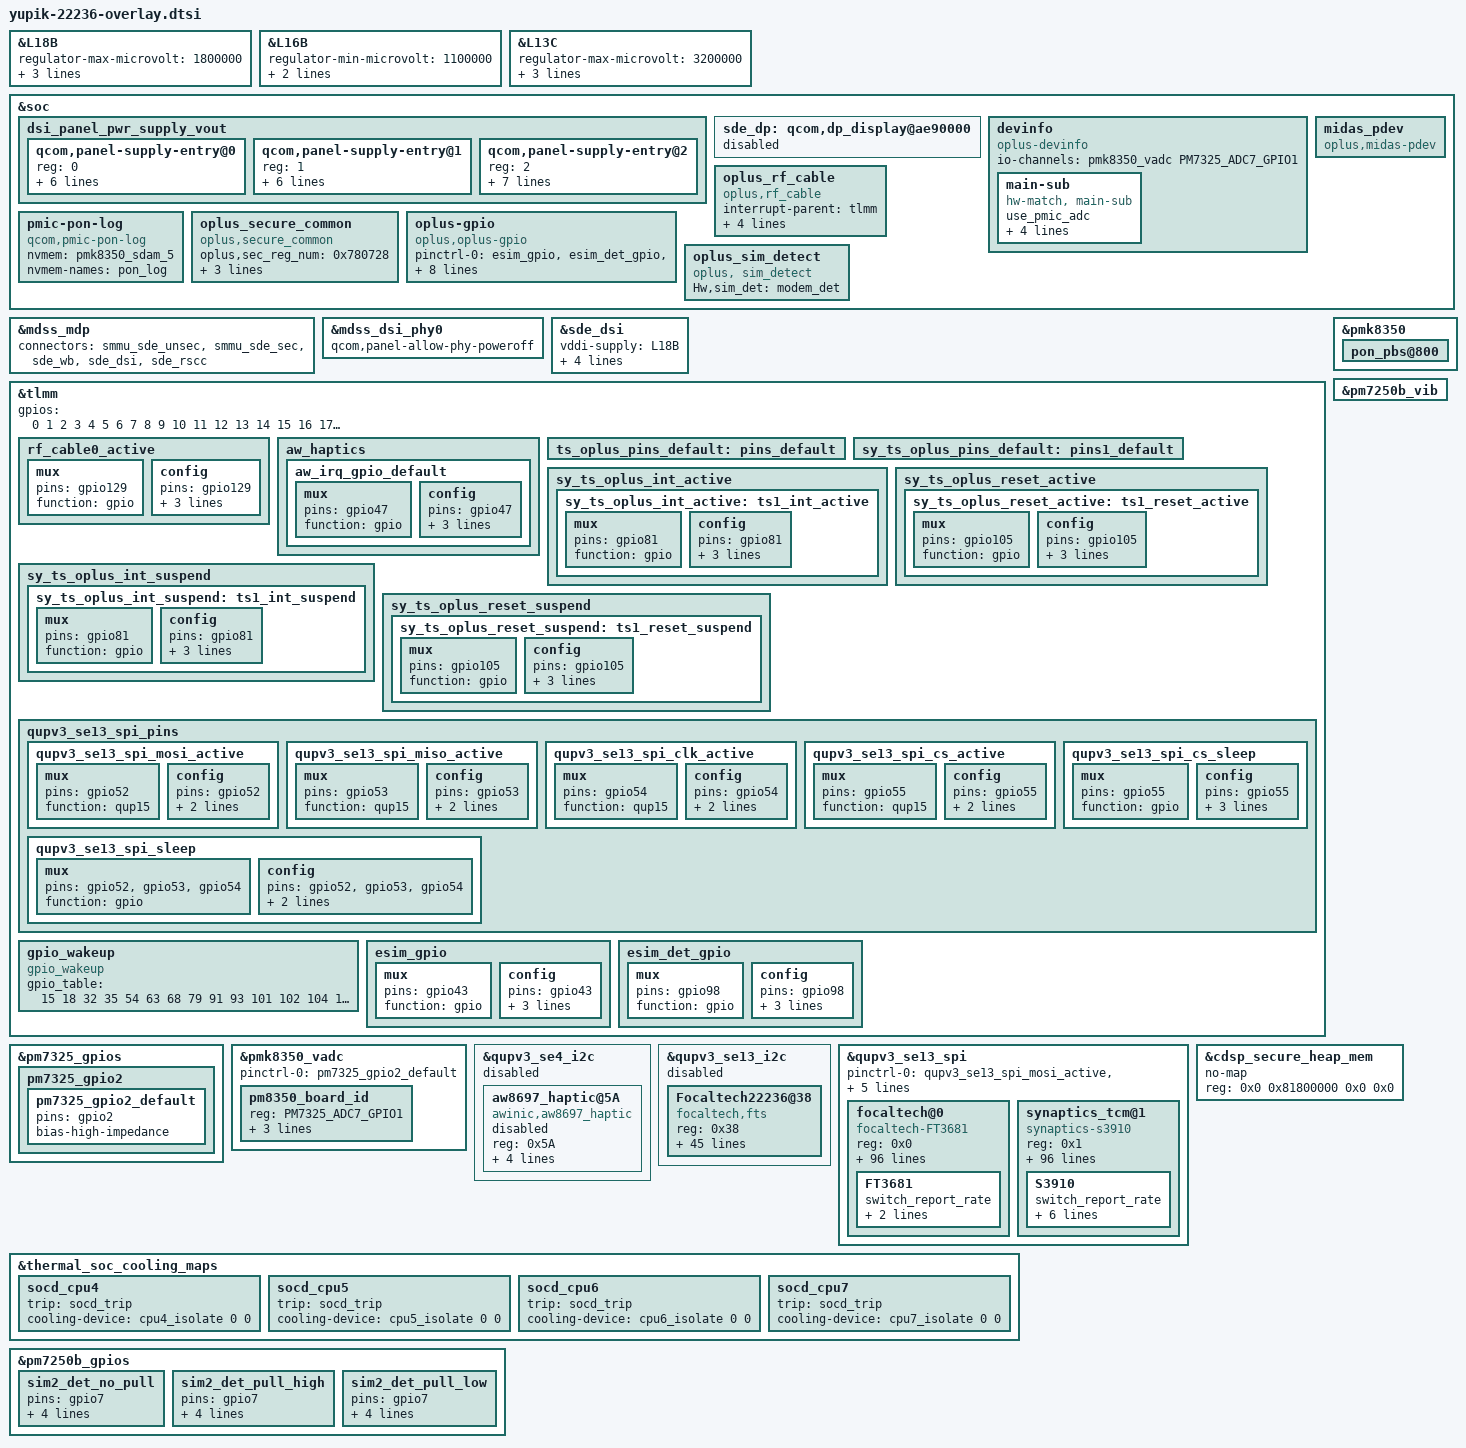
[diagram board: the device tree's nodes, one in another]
/*#ifdef OPLUS_FEATURE_SENSOR_DRIVER*/
#include "sensor/garbo-sensor-22236.dtsi"
/*#endif*/

//#ifdef OPLUS_FEATURE_UFF_FINGERPRINT
#include "oplus_uff_fingerprint_garbo.dtsi"
//#endif

//#ifdef OPLUS_FEATURE_CHG_BASIC
#include "charge/garbo_charge.dtsi"
//#endif

//#ifdef OPLUS_BUG_STABILITY
#include "dsi_panel-oplus22236-tm-ili7838a-1080-2412-dsc-cmd.dtsi"
#include "dsi_panel-oplus22236-boe-nt37705-1080-2412-dsc-cmd.dtsi"
//VDDI
&L18B {
	regulator-max-microvolt = <1800000>;
	qcom,init-voltage = <1800000>;
	qcom,proxy-consumer-enable;
	qcom,proxy-consumer-current = <243000>;
};
//VDDR(VOUT)
&L16B {
	regulator-min-microvolt = <1100000>;
	regulator-man-microvolt = <1300000>;
	qcom,min-dropout-voltage = <70000>;
};
//VCI
&L13C {
	regulator-max-microvolt = <3200000>;
	qcom,init-voltage = <3000000>;
	qcom,proxy-consumer-enable;
	qcom,proxy-consumer-current = <10000>;
};
&soc {
	dsi_panel_pwr_supply_vout: dsi_panel_pwr_supply_vout {
		#address-cells = <1>;
		#size-cells = <0>;

		qcom,panel-supply-entry@0 {
			reg = <0>;
			qcom,supply-name = "vddi";
			qcom,supply-min-voltage = <1800000>;
			qcom,supply-max-voltage = <1800000>;
			qcom,supply-enable-load = <60700>;
			qcom,supply-disable-load = <80>;
			qcom,supply-post-on-sleep = <0>;
		};
		qcom,panel-supply-entry@1 {
			reg = <1>;
			qcom,supply-name = "vddr";
			qcom,supply-min-voltage = <1204000>;
			qcom,supply-max-voltage = <1204000>;
			qcom,supply-enable-load = <60700>;
			qcom,supply-disable-load = <80>;
			qcom,supply-post-on-sleep = <0>;
		};
		qcom,panel-supply-entry@2 {
			reg = <2>;
			qcom,supply-name = "vci";
			qcom,supply-min-voltage = <3000000>;
			qcom,supply-max-voltage = <3000000>;
			qcom,supply-enable-load = <10000>;
			qcom,supply-disable-load = <0>;
			qcom,supply-post-on-sleep = <11>;
			qcom,supply-pre-off-sleep = <2>;
		};
	};
};

// &pm8008i_chip {
// 	/delete-property/ pinctrl-names;
// 	/delete-property/ pinctrl-0;
// };

&soc {
	sde_dp: qcom,dp_display@ae90000 {
		status = "disabled";
	};
};
&mdss_mdp {
	connectors = <&smmu_sde_unsec &smmu_sde_sec &sde_wb &sde_dsi &sde_rscc>;
};

&mdss_dsi_phy0 {
	qcom,panel-allow-phy-poweroff;
};

&sde_dsi {
	/delete-property/ lab-supply;
	/delete-property/ ibb-supply;
	vddi-supply = <&L18B>;	//PM7350C LDO12
	vddr-supply = <&L16B>;	//PM8008 LDO5
	vci-supply = <&L13C>;	//PM7350C LDC13
	qcom,dsi-default-panel = <&dsi_oplus22236_boe_nt37705_1080_2412_dsc_cmd>;
};
//#endif /* OPLUS_BUG_STABILITY */

&tlmm {

	rf_cable0_active: rf_cable0_active {
		mux {
			pins = "gpio129";
			function = "gpio";
		};
		config {
			pins = "gpio129";
			drive-strength = <2>;
			input-enable;
			bias-pull-up;
		};
	};

};



&pm7325_gpios {
	pm7325_gpio2 {
		pm7325_gpio2_default: pm7325_gpio2_default {
			pins = "gpio2";
			bias-high-impedance;
		};
	};
};

&pmk8350 {
        pon_pbs@800 {
                status = "ok";
        };
};

&pmk8350_vadc {
	pinctrl-names = "default";

	pinctrl-0 = <&pm7325_gpio2_default>;

	pm8350_board_id {
		reg = <PM7325_ADC7_GPIO1>;
		label = "pm8350_board_id";
		//qcom,ratiometric;
		qcom,hw-settle-time = <200>;
		qcom,pre-scaling = <1 1>;
	};
};



&soc {
	devinfo {
		compatible = "oplus-devinfo";

		//pinctrl-names = "active", "sleep";
		//pinctrl-0 = <&hw_id_active>;
		//pinctrl-1 = <&hw_id_sleep>;

		io-channels= <&pmk8350_vadc PM7325_ADC7_GPIO1>;
		io-channel-names= "vph_pwr_voltage_sub";

		main-sub {
			compatible = "hw-match, main-sub";
			use_pmic_adc;
			adc_ranges = <0 80
					81 180
					181 300
					301 420
					421 550
					551 650
					651 760
					761 850
					851 950
					951 1050
					1051 1150
					1151 1300
					1301 1599
					1600 1900>;
			aboard-patterns = <0 1 2>;

			/*main board*/
			match-projects = <22235 22235 22236>;

			/*rf type*/
			//rf_match_support;
			//rf-patterns = <0 0>;
		};
	};

	oplus_rf_cable {
		compatible = "oplus,rf_cable";
		interrupt-parent = <&tlmm>;
		rf_cable_support_num = <1>;
		rf,cable0-gpio = <&tlmm 129 0>;
		rf,cable-support-timer = <0>;
		pinctrl-names = "rf_cable_active";
		pinctrl-0 = <&rf_cable0_active>;
	};

    midas_pdev {
        compatible = "oplus,midas-pdev";
    };
};

&pm7250b_vib {
	status = "ok";
};

&tlmm {
	aw_haptics: aw_haptics {
		aw_irq_gpio_default: aw_irq_gpio_default {
			mux {
				pins = "gpio47";
				function = "gpio";
			};

			config {
				pins = "gpio47";
				drive-strength = <2>;
				input-enable;
				bias-pull-up; /*PULL UP*/
				//bias-disable;
			};
		};
	};

	ts_oplus_pins_default: pins_default {
	};

    sy_ts_oplus_pins_default: pins1_default {
	};

	sy_ts_oplus_int_active {
        sy_ts_oplus_int_active: ts1_int_active {
            mux {
                pins = "gpio81";
                function = "gpio";
            };

            config {
                pins = "gpio81";
                drive-strength = <8>;
                bias-disable;
                input-enable;
            };
        };
    };

    sy_ts_oplus_reset_active {
        sy_ts_oplus_reset_active: ts1_reset_active {
            mux {
                pins = "gpio105";
                function = "gpio";
            };

            config {
                pins = "gpio105";
                drive-strength = <8>;
                output-low;
                bias-disable;
            };
        };
    };

	sy_ts_oplus_int_suspend {
        sy_ts_oplus_int_suspend: ts1_int_suspend {
            mux {
                pins = "gpio81";
                function = "gpio";
            };

            config {
                pins = "gpio81";
                drive-strength = <8>;
                output-low;
                bias-disable;
            };
        };
    };

	sy_ts_oplus_reset_suspend {
        sy_ts_oplus_reset_suspend: ts1_reset_suspend {
            mux {
                pins = "gpio105";
                function = "gpio";
            };

            config {
                pins = "gpio105";
                drive-strength = <8>;
                output-low;
                bias-disable;
            };
        };
    };
};

&qupv3_se4_i2c  {
	//status = "ok";
	/* AWINIC AW8697 Haptic */
	aw8697_haptic@5A {
		compatible = "awinic,aw8697_haptic";
		reg = <0x5A>;
		reset-gpio = <&tlmm 55 0>;
		irq-gpio = <&tlmm 47 0>;
		status = "disabled";
		qcom,device_id = <815>;//19066

		pinctrl-names = "default";
		pinctrl-0 = <&aw_irq_gpio_default>;
	};
	/* AWINIC AW8697 Haptic End */
};
//#endif

&qupv3_se4_i2c {
	status = "disable";
};
&qupv3_se13_i2c {
	#address-cells = <1>;
	#size-cells = <0>;

	status = "disable";

	Focaltech22236@38 {
		compatible = "focaltech,fts";
		reg = <0x38>;
		chip-name = "FT3518";

		/* Interrupt && Irq-gpio */
		interrupt-parent = <&tlmm>;
		interrupts = <81 0x2002>;

		/* Power Config */
		vdd_2v8-supply = <&L3C>;
		vcc_1v8-supply = <&L12C>;
		vdd_2v8_volt = <3008000>;

		/* Interrupt && Irq-gpio */
                /* Other HW Resource */
		irq-gpio = <&tlmm 81 0x2002>;
		reset-gpio = <&tlmm 105 0x1>;
		/*pinctrl-names = "default";*/
		/*pinctrl-0 = <&ts_int_active &ts_reset_active>;*/

		pinctrl-names = "pmx_ts_active","pmx_ts_suspend",
					"pmx_ts_release";

		pinctrl-0 = <&ts_active>;
		pinctrl-1 = <&ts_int_suspend &ts_reset_suspend>;
		pinctrl-2 = <&ts_release>;

		//panel = <&dsi_oplus22236_samsung_s6e3fc3_1080_2400_dsc_cmd>;

		touchpanel,max-num-support = <10>;
		touchpanel,tx-rx-num = <16 34>;
		touchpanel,panel-coords = <4320 9600>;
		touchpanel,display-coords = <1080 2400>;
		touchpanel,touchmajor-limit = <0 216>;
		touchpanel,smooth-level = <255 2 15 25 45 60>;
		touchpanel,smooth-level-charging = <255 15 20 25 45 60>;
		touchpanel,sensitive-level = <255 20 17 14 10 8>;
		touchpanel,high-frame-rate-time = <20>;
		project_id = <22236>;
		panel_type = <8>;
		tp_type = <8>;
		firmware_name = "0xAA29000";
		platform_support_project = <22236>;
		platform_support_project_dir = <22236>;
		platform_support_project_commandline = "default_commandline";
		/* SW Support Feature Control */
		black_gesture_support;
		fw_edge_limit_support;
		pressure_report_support;
		charger_pump_support;
		game_switch_support;
		smart_gesture_support;
		fw_update_app_support;
		fingerprint_underscreen_support;
		headset_pump_support;
		//esd_handle_support;
		new_set_irq_wake_support;
		irq_need_dev_resume_ok;
		health_monitor_support;
		high_resolution_support;
		lcd_tp_refresh_support;
		/*
		*Virtual Key Config:
		*1:touchpanel,button-type: <virtualkey_type  supportted_button-map>
		*virtualkey_type:
		*Type 1: using board_properties
		*Type 2: using same IC (button zone&& touch zone are seprate)
		*Type 3: using diffrent IC (button zone&& touch zone are seprate)
		*Type 4: No need of virtual key process
		*supportted_button-map:select|menu|home|back
		*
		*2:touchpanel,button-map
		*type (X1,Y1)(X2,Y2)(X3,Y3)(Width_X,Hight_Y)--Only when button-type is 0
		*/
		touchpanel,button-type = <4>;
		touchpanel.button-TRx = <0 0>;
	};
};

&tlmm {
//#ifdef OPLUS_FEATURE_TP_BASIC

	qupv3_se13_spi_pins: qupv3_se13_spi_pins {
		qupv3_se13_spi_mosi_active: qupv3_se13_spi_mosi_active {
			mux {
				pins = "gpio52";
				function = "qup15";
			};

			config {
				pins = "gpio52";
				drive-strength = <6>;
				bias-disable;
			};
		};

		qupv3_se13_spi_miso_active: qupv3_se13_spi_miso_active {
			mux {
				pins = "gpio53";
				function = "qup15";
			};

			config {
				pins = "gpio53";
				drive-strength = <6>;
				bias-disable;
			};
		};

		qupv3_se13_spi_clk_active: qupv3_se13_spi_clk_active {
			mux {
				pins = "gpio54";
				function = "qup15";
			};

			config {
				pins = "gpio54";
				drive-strength = <6>;
				bias-disable;
			};
		};

		qupv3_se13_spi_cs_active: qupv3_se13_spi_cs_active {
			mux {
				pins = "gpio55";
				function = "qup15";
			};

			config {
				pins = "gpio55";
				drive-strength = <6>;
				bias-disable;
			};
		};

		qupv3_se13_spi_sleep: qupv3_se13_spi_sleep {
			mux {
				pins = "gpio52", "gpio53",
						"gpio54";
				function = "gpio";
			};

			config {
				pins = "gpio52", "gpio53",
						"gpio54";
				drive-strength = <6>;
				bias-disable;
			};
		};

		qupv3_se13_spi_cs_sleep: qupv3_se13_spi_cs_sleep {
			mux {
				pins = "gpio55";
				function = "gpio";
			};

			config {
				pins = "gpio55";
				drive-strength = <6>;
				bias-disable;
				output-high;
			};
		};
	};
};


&qupv3_se13_spi {
	/delete-property/ pinctrl-0;
	/delete-property/ pinctrl-1;
	pinctrl-0 = <&qupv3_se13_spi_mosi_active>, <&qupv3_se13_spi_miso_active>,
				<&qupv3_se13_spi_clk_active>, <&qupv3_se13_spi_cs_active>;
	pinctrl-1 = <&qupv3_se13_spi_sleep>, <&qupv3_se13_spi_cs_sleep>;
};

&qupv3_se13_spi {
    status = "ok";
    #address-cells = <1>;
    #size-cells = <0>;

	focaltech@0{
        status = "ok";
        compatible = "focaltech-FT3681";
        reg = <0x0>;
        spi-max-frequency = <12000000>;
        chip-name = "FT3681";

        /* Interrupt && Irq-gpio */
        interrupt-parent = <&tlmm>;
        interrupts = <81 0x2002>;
        irq-gpio = <&tlmm 81 0x2002>;
        reset-gpio = <&tlmm 105 0x1>;

        /* Power Config */
        vdd_2v8-supply = <&L3C>;
        vcc_1v8-supply = <&L12C>;
        vdd_2v8_volt = <3000000>;
        /* Other HW Resource */

        pinctrl-names = "default";
        pinctrl-0 = <&ts_oplus_pins_default>;

        panel = <&dsi_oplus22236_boe_nt37705_1080_2412_dsc_cmd>;

        touchpanel,max-num-support = <10>;
        touchpanel,tx-rx-num = <16 36>;
        touchpanel,panel-coords = <8640 19296>;
        touchpanel,display-coords = <1080 2412>;
        touchpanel,touchmajor-limit = <128 216>;
        touchpanel,smooth-level = <0 110 115 120 140 155>;
        touchpanel,smooth-level-charging = <0 110 115 120 140 155>;
        touchpanel,sensitive-level = <0 20 16 13 10 8>;
        touchpanel,single-optimized-time = <8>;
        touchpanel,high-frame-rate-time = <60>;
        touchpanel,irq_need_dev_resume_time = <250>;

        project_id = <22236>;
        vid_len = <2>;
        firmware_name = "0xAC0380D01";
        touchpanel,tp-index = <0>;
        touchpanel,tp_ic_type = <2>;
        panel_type = <3>;
        // type of tp_dev ,TP-SAMSUNG = 8;
        platform_support_project = <22236>;
        platform_support_project_dir = <22235>;
        platform_support_project_commandline = "mdss_dsi_oplus22236_boe_nt37705_1080_2412_dsc_cmd";

        prevention,curved_screen_V2;
        prevention,grip_disable_level = <6>;
        prevention,updelay_time_ms = <30>;
        prevention,makeup_cnt_weight = <4 1 2 2 2>;
        prevention,large_corner_range = <960 2400>;
        prevention,large_corner_judge_condition = <500 300 800 6 6>;
        prevention,trx_reject_condition = <8 7 7>;
        prevention,trx_strict_reject_condition = <7 6 6>;
        prevention,large_judge_time_ms = <500 50 30>;
        prevention,large_exit_condition = <15 12 2>;
        prevention,single_channel_width = <256 256>;
        prevention,normal_tap_condition = <10 300>;
        prevention,long_edge_condition = <230 100 180 80>;
        prevention,long_strict_edge_condition = <170 80>;
        prevention,long_fingerhold_condition = <50 6 4 4>;
        prevention,short_edge_condition = <230 100 180 80>;
        prevention,short_strict_edge_condition = <160 60>;
        prevention,large_strict_exit_condition = <5 5>;
        prevention,top_corner_config = <400 1200 380>;
        prevention,edge_swipe_config = <240 800>;

        prevention,curved_screen_V4;
        prevention,long_eliminate_point_type = <2 8640 6640 210 19296 300 1>;
        prevention,long_fingerhold_condition2 = <560 1600 0 0>;
        prevention,top_corner_config2 =<3 80 420 1200 0>;
        prevention,hor_long_top_corner_config =<240 1600 0 0>;
        prevention,top_middle_config =<8640 800 800 0>;
        prevention,corner_eliminate_point_type =<0 960 1600 1>;
        prevention,finger_hold_differ_size = <1 0 360 300>;
        prevention,finger_hold_max_rx_exit_distance = <5 350 1700>;
        prevention,max_rx_exit_distance = <1 5 90 350 1400>;
        prevention,dynamic_finger_hold_exit_distance = <1 290 1700 390>;

        /* SW Support Feature Control */
        black_gesture_support;
        sportify_aod_gesture_support;
        pressure_report_support;
        charger_pump_support;
        game_switch_support;
        smart_gesture_support;
        fw_update_app_support;
        fingerprint_underscreen_support;
        freq_hop_simulate_support;
        screenoff_fingerprint_info_support;
        irq_need_dev_resume_ok;
        //enable_point_auto_change;
        kernel_grip_support;
        exception_upload_support;
        //grip_no_driver_support;
        health_monitor_support;
        black_gesture_indep_support;
        temperature_detect_shellback_support;
        snr_read_support;
        disable_suspend_irq_handler_support;
        tp_data_record_support;
        /*
         *Virtual Key Config:
         *1:touchpanel,button-type: <virtualkey_type  supportted_button-map>
         *virtualkey_type:
         *Type 1: using board_properties
         *Type 2: using same IC (button zone&& touch zone are seprate)
         *Type 3: using diffrent IC (button zone&& touch zone are seprate)
         *Type 4: No need of virtual key process
         *supportted_button-map:select|menu|home|back
         *
         *2:touchpanel,button-map
         *type (X1,Y1)(X2,Y2)(X3,Y3)(Width_X,Hight_Y)--Only when button-type is 0
         */
        touchpanel,button-type = <4>;
        touchpanel.button-TRx = <0 0>;

        FT3681 {
            switch_report_rate;
            report_rate_default = <60>;
            report_rate_game_value = <0x02>;
        };
    };

    synaptics_tcm@1{
        status = "ok";
        compatible = "synaptics-s3910";
        reg = <0x1>;
        spi-max-frequency = <12000000>;
        chip-name = "S3910";

        /* Interrupt && Irq-gpio */
		interrupt-parent = <&tlmm>;
        //interrupts = <81 0x2008>;
        irq-gpio = <&tlmm 81 0x2008>;
        reset-gpio = <&tlmm 105 0x1>;

        /* Power Config */
        vdd_2v8-supply = <&L3C>;
        vcc_1v8-supply = <&L12C>;
        vdd_2v8_volt = <3000000>;
        /* Other HW Resource */

        pinctrl-names = "default",  "oplus_int_active",
		"oplus_reset_active", "oplus_int_suspend",
		"oplus_reset_suspend";
        pinctrl-0 = <&sy_ts_oplus_pins_default>;
        pinctrl-1 = <&sy_ts_oplus_int_active>;
        pinctrl-2 = <&sy_ts_oplus_reset_active>;
        pinctrl-3 = <&sy_ts_oplus_int_suspend>;
        pinctrl-4 = <&sy_ts_oplus_reset_suspend>;

        panel = <&dsi_oplus22236_tm_ili7838a_1080_2412_dsc_cmd>;

        touchpanel,max-num-support = <10>;
        touchpanel,tx-rx-num = <16 36>;
        touchpanel,panel-coords = <10800 24120>;
        touchpanel,display-coords = <1080 2412>;
        touchpanel,touchmajor-limit = <128 216>;
        touchpanel,int-mode = <1>; /*0: interrupt and disable, 1:interrupt and not disable*/
        touchpanel,smooth-level = <0 1 2 4 7 9>;
        touchpanel,smooth-level-charging = <0 2 4 7 8 9>;
        touchpanel,sensitive-level = <0 70 55 40 25 10>;
        touchpanel,single-optimized-time = <8>;
        touchpanel,high-frame-rate-time = <60>;
        touchpanel,irq_need_dev_resume_time = <250>;

        project_id = <22236>;
        vid_len = <2>;
        touchpanel,tp-index = <0>;
        //touchpanel,tp_ic_type = <2>;
        panel_type = <7>;
        // type of tp_dev ,TP-SAMSUNG = 8;
        platform_support_project = <22236>;
        platform_support_project_dir = <22235>;
        platform_support_project_commandline = "mdss_dsi_oplus22236_tm_ili7838a_1080_2412_dsc_cmd";

        prevention,curved_screen_V2;
        prevention,grip_disable_level = <6>;
        prevention,updelay_time_ms = <30>;
        prevention,makeup_cnt_weight = <4 1 2 2 2>;
        prevention,large_corner_range = <1200 3000>;
        prevention,large_corner_judge_condition = <500 300 1000 6 6>;
        prevention,trx_reject_condition = <8 7 7>;
        prevention,trx_strict_reject_condition = <8 6 6>;
        prevention,large_judge_time_ms = <500 50 30>;
        prevention,large_exit_condition = <8 8 2>;
        prevention,single_channel_width = <320 320>;
        prevention,normal_tap_condition = <10 300>;
        prevention,long_edge_condition = <200 90 180 80>;
        prevention,long_strict_edge_condition = <160 60>;
        prevention,long_fingerhold_condition = <50 6 4 4>;
        prevention,short_edge_condition = <200 90 180 80>;
        prevention,short_strict_edge_condition = <160 60>;
        prevention,large_strict_exit_condition = <4 4>;
        prevention,top_corner_config = <500 1500 480>;
        prevention,edge_swipe_config = <300 1000>;

        prevention,curved_screen_V4;
        prevention,long_eliminate_point_type = <2 10800 8040 220 24120 300 1>;
        prevention,long_fingerhold_condition2 = <700 2000 0 0>;
        prevention,top_corner_config2 =<3 80 420 1500 0>;
        prevention,hor_long_top_corner_config =<300 2000 0 0>;
        prevention,top_middle_config =<10800 1000 1000 0>;
        prevention,corner_eliminate_point_type =<0 1200 2000 1>;
        prevention,finger_hold_differ_size = <1 0 300 300>;
        prevention,finger_hold_max_rx_exit_distance = <5 300 2000>;
        prevention,max_rx_exit_distance = <1 5 150 300 2000>;
        prevention,dynamic_finger_hold_exit_distance = <1 300 2000 450>;

        /* SW Support Feature Control */
        black_gesture_support;
        sportify_aod_gesture_support;
        pressure_report_support;
        charger_pump_support;
        game_switch_support;
        smart_gesture_support;
        fw_update_app_support;
        fingerprint_underscreen_support;
        freq_hop_simulate_support;
        report_flow_unlock_support;
        screenoff_fingerprint_info_support;
        irq_need_dev_resume_ok;
        enable_point_auto_change;
        kernel_grip_support;
        exception_upload_support;
        //grip_no_driver_support;
        health_monitor_support;
        black_gesture_indep_support;
        snr_read_support;
        /*
         *Virtual Key Config:
         *1:touchpanel,button-type: <virtualkey_type  supportted_button-map>
         *virtualkey_type:
         *Type 1: using board_properties
         *Type 2: using same IC (button zone&& touch zone are seprate)
         *Type 3: using diffrent IC (button zone&& touch zone are seprate)
         *Type 4: No need of virtual key process
         *supportted_button-map:select|menu|home|back
         *
         *2:touchpanel,button-map
         *type (X1,Y1)(X2,Y2)(X3,Y3)(Width_X,Hight_Y)--Only when button-type is 0
         */
        touchpanel,button-type = <4>;
        touchpanel.button-TRx = <0 0>;

        S3910 {
            switch_report_rate;
            report_rate_default = <60>;
            report_rate_game_value = <0x03>;
            fps_report_rate = <60 2 90 3 120 3>;//1:360Hz 2:125Hz 3:240Hz
            fwupdate_bootloader = <1>;
            default_gesture_mask = <8191>;
            normal_config_version = <2>;
        };
    };
};

//Baihang.Wang 2021/08/26 add for disable wake-up function of NC-GPIO
&tlmm {
	gpio_wakeup: gpio_wakeup {
		compatible = "gpio_wakeup";
		gpio_table = <15 18 32 35 54 63 68 79 91 93 101 102 104 130 136 155 156 157 158 174 82 56 59>;
	};
};

/* delete low battery policy for performance */
&thermal_soc_cooling_maps {
	socd_cpu4 {
		trip = <&socd_trip>;
		cooling-device = <&cpu4_isolate 0 0>;
	};

	socd_cpu5 {
		trip = <&socd_trip>;
		cooling-device = <&cpu5_isolate 0 0>;
	};

	socd_cpu6 {
		trip = <&socd_trip>;
		cooling-device = <&cpu6_isolate 0 0>;
	};

	socd_cpu7 {
		trip = <&socd_trip>;
		cooling-device = <&cpu7_isolate 0 0>;
	};
};

&soc {
	pmic-pon-log {
		compatible = "qcom,pmic-pon-log";
		nvmem = <&pmk8350_sdam_5>;
		nvmem-names = "pon_log";
	};
};

//#ifdef OPLUS_FEATURE_FINGERPRINT
&cdsp_secure_heap_mem {
	no-map;
	reg = <0x0 0x81800000 0x0 0x0>;
};
//#endif /*OPLUS_FEATURE_FINGERPRINT*/

//#ifdef OPLUS_FEATURE_CHG_BASIC//BSP.Chg.Basic, 2022/07/28 delete qcom gpio32,33
&tlmm {
	/* yupik_reserved_gpios[] = {32, 33, 48, 49, 50, 51, -1}; */
	gpios = /bits/ 16 <
			0 1 2 3 4 5 6 7 8 9
			10 11 12 13 14 15 16 17 18 19
			20 21 22 23 24 25 26 27 28 29
			30 31 32 33 34 35 36 37 38 39
			40 41 42 43 44 45 46 47
			      52 53 54 55 56 57 58 59
			60 61 62 63 64 65 66 67 68 69
			70 71 72 73 74 75 76 77 78 79
			80 81 82 83 84 85 86 87 88 89
			90 91 92 93 94 95 96 97 98 99
			100 101 102 103 104 105 106 107 108 109
			110 111 112 113 114 115 116 117 118 119
			120 121 122 123 124 125 126 127 128 129
			130 131 132 133 134 135 136 137 138 139
			140 141 142 143 144 145 146 147 148 149
			150 151 152 153 154 155 156 157 158 159
			160 161 162 163 164 165 166 167 168 169
			170 171 172 173 174 175
			>;
};

&soc {
	oplus_secure_common {
		compatible = "oplus,secure_common";
		oplus,sec_reg_num = <0x780728>;
		oplus,sec_en_anti_reg = <0x7801D4>;
		oplus,sec_override1_reg = <0x7860C0>;
		oplus,override1_en_value = <0x1>;
	};
};

&tlmm {
	//#ifdef OPLUS_FEATRUE_ESIM
	esim_gpio: esim_gpio {
		mux {
			pins = "gpio43";
			function = "gpio";
		};
		config {
			pins = "gpio43";
			bias-disable; /* NO pull */
			drive-strength = <2>; /* 2 MA */
			output-high;
		};
	};

	esim_det_gpio: esim_det_gpio {
		mux {
			pins = "gpio98";
			function = "gpio";
		};
		config {
			pins = "gpio98";
			bias-disable; /* NO pull */
			drive-strength = <2>; /* 2 MA */
			output-high;
		};
	};
};

&pm7250b_gpios {
	sim2_det_no_pull: sim2_det_no_pull {
			pins = "gpio7";
			function = "normal";
			input-enable;
			power-source = <0>;
			bias-disable;
	};

	sim2_det_pull_high: sim2_det_pull_high {
			pins = "gpio7";
			function = "normal";
			input-enable;
			power-source = <0>;
			bias-pull-up;
	};

	sim2_det_pull_low: sim2_det_pull_low {
			pins = "gpio7";
			function = "normal";
			input-enable;
			power-source = <0>;
			bias-pull-down;
	};
	//#endif /* OPLUS_FEATRUE_ESIM */
};
&soc {
	//#ifdef OPLUS_FEATRUE_ESIM
	oplus-gpio {
		compatible = "oplus,oplus-gpio";
		pinctrl-names = "default", "sim2_det_no_pull", "sim2_det_pull_high", "sim2_det_pull_low";
		pinctrl-0 = <&esim_gpio &esim_det_gpio &sim2_det_no_pull>;
		pinctrl-1 = <&sim2_det_no_pull>;
		pinctrl-2 = <&sim2_det_pull_high>;
		pinctrl-3 = <&sim2_det_pull_low>;
		oplus,oplus-gpio-esim = <&tlmm 43 0>;
		oplus,oplus-esim-det = <&tlmm 98 0>;
		oplus,oplus-sim2-det = <&pm7250b_gpios 7 0>;
                oplus,uim-reset-pin = "modem_solution";
	};
	//#endif /* OPLUS_FEATRUE_ESIM */
	oplus_sim_detect {
		compatible = "oplus, sim_detect";
		Hw,sim_det = "modem_det";
	};
};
